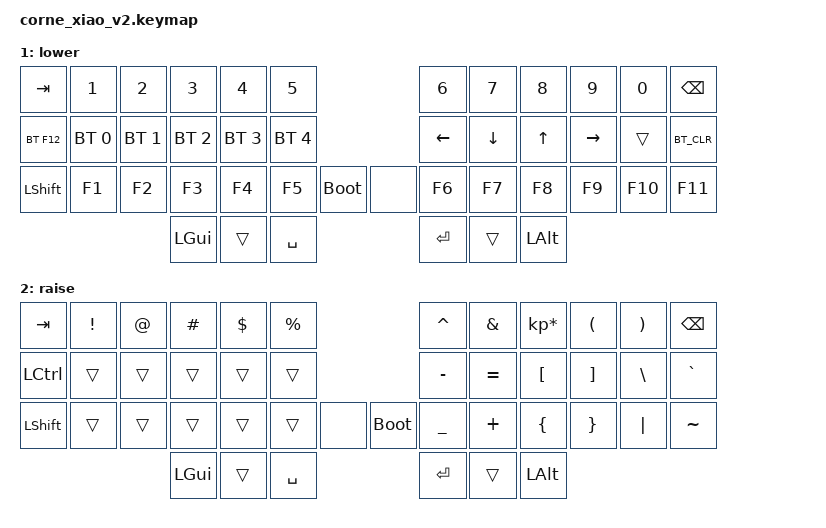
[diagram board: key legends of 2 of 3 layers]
#include <behaviors.dtsi>
#include <dt-bindings/zmk/keys.h>
#include <dt-bindings/zmk/bt.h>

/ {
    behaviors {
        hml: home_row_mod_left {
            compatible = "zmk,behavior-hold-tap";
            #binding-cells = <2>;
            flavor = "balanced";
            require-prior-idle-ms = <150>;
            tapping-term-ms = <280>;
            quick-tap-ms = <175>;
            bindings = <&kp>, <&kp>;
            // Right-hand side key positions (placeholder, adjust for your board!)
            hold-trigger-key-positions = < 14 15 16 17 18 19 20 21 22 23 24 25 >;
            hold-trigger-on-release;
        };

        hmr: home_row_mod_right {
            compatible = "zmk,behavior-hold-tap";
            #binding-cells = <2>;
            flavor = "balanced";
            require-prior-idle-ms = <150>;
            tapping-term-ms = <280>;
            quick-tap-ms = <175>;
            bindings = <&kp>, <&kp>;
            // Left-hand side key positions (placeholder, adjust for your board!)
            hold-trigger-key-positions = < 0 1 2 3 4 5 6 7 8 9 10 11 >;
            hold-trigger-on-release;
        };
    };

    combos {
        compatible = "zmk,combos";
        combo_studio_unlock {
            timeout-ms = <50>;
            key-positions = <0 1>;
            bindings = <&studio_unlock>;
        };
    };
};

 / {
    keymap {
        compatible = "zmk,keymap";

        default_layer {
            display-name = "base";
            sensor-bindings = <&inc_dec_kp C_VOL_UP C_VOL_DN &inc_dec_kp PG_UP PG_DN>;

            // -------------------------------------------------------------------------------------------------
            // |  TAB |  Q  |  W  |  E  |  R  |  T  |                    |  Y  |  U   |  I  |  O  |  P  | BKSP |
            // | CTRL |  A  |  S  |  D  |  F  |  G  |                    |  H  |  J   |  K  |  L  |  ;  |  '   |
            // | SHFT |  Z  |  X  |  C  |  V  |  B  |  MUTE  |  |        |  N  |  M   |  ,  |  .  |  /  | ESC  |
            //                    | GUI | LWR | SPC |                    | ENT | RSE  | ALT |
            bindings = <
&kp TAB   &kp Q &kp W &kp E     &kp R &kp T                       &kp Y   &kp U     &kp I     &kp O   &kp P    &kp BSPC

&hml LCTRL A   &hml LALT S &hml LGUI D &hml LSHFT F &kp G         &kp H   &hmr RSHFT J &hmr RGUI K &hmr RALT L &hmr RCTRL SEMI &kp SQT

&kp LSHFT &kp Z &kp X &kp C     &kp V &kp B     &kp C_MUTE &none  &kp N   &kp M &kp COMMA &kp DOT &kp FSLH &kp ESC

                       &kp LGUI &mo 1 &kp SPACE                   &kp RET &mo 2 &kp LALT
            >;
        };

        lower_layer {
            display-name = "lower";
            sensor-bindings = <&inc_dec_kp C_VOL_UP C_VOL_DN &inc_dec_kp PG_UP PG_DN>;

            // ------------------------------------------------------------------------------------------------
            // |  TAB |  1  |  2  |  3  |  4  |  5  |                    |  6  |  7  |  8  |  9  |  0  | BKSP |
            // | BTCLR| BT1 | BT2 | BT3 | BT4 | BT5 |                    | LFT | DWN |  UP | RGT |     |  F12 |
            // | SHFT | F1  | F2  | F3  | F4  | F5  |  boot  |  |        |  F6 | F7  | F8  | F9  | F10 |  F11 |
            //                    | GUI |     | SPC |                    | ENT |     | ALT |
            bindings = <
&kp TAB    &kp N1       &kp N2       &kp N3       &kp N4       &kp N5                         &kp N6   &kp N7   &kp N8 &kp N9    &kp N0  &kp BSPC
&bt F12    &bt BT_SEL 0 &bt BT_SEL 1 &bt BT_SEL 2 &bt BT_SEL 3 &bt BT_SEL 4                   &kp LEFT &kp DOWN &kp UP &kp RIGHT &trans  &kp BT_CLR
&kp LSHFT  &kp F1       &kp F2       &kp F3       &kp F4       &kp F5       &bootloader &none &kp F6   &kp F7   &kp F8 &kp F9    &kp F10 &kp F11
                                     &kp LGUI     &trans       &kp SPACE                      &kp RET  &trans   &kp LALT
            >;
        };

        raise_layer {
            display-name = "raise";
            sensor-bindings = <&inc_dec_kp C_VOL_UP C_VOL_DN &inc_dec_kp PG_UP PG_DN>;

            // ------------------------------------------------------------------------------------------------
            // |  TAB |  !  |  @  |  #  |  $  |  %  |                    |  ^  |  &  |  *  |  (  |  )  | BKSP |
            // | CTRL |     |     |     |     |     |                    |  -  |  =  |  [  |  ]  |  \  |  `   |
            // | SHFT |     |     |     |     |     |        |  |  boot  |  _  |  +  |  {  |  }  | "|" |  ~   |
            //                    | GUI |     | SPC |                    | ENT |     | ALT |
            bindings = <
&kp TAB   &kp EXCL &kp AT &kp HASH &kp DLLR &kp PRCNT                   &kp CARET &kp AMPS  &kp KP_MULTIPLY &kp LPAR &kp RPAR &kp BSPC
&kp LCTRL &trans   &trans &trans   &trans   &trans                      &kp MINUS &kp EQUAL &kp LBKT        &kp RBKT &kp BSLH &kp GRAVE
&kp LSHFT &trans   &trans &trans   &trans   &trans    &none &bootloader &kp UNDER &kp PLUS  &kp LBRC        &kp RBRC &kp PIPE &kp TILDE
                          &kp LGUI &trans   &kp SPACE                   &kp RET   &trans    &kp LALT
            >;
        };

        extra1 {
            display-name = "extra1";
            status = "reserved";
        };

        extra2 {
            display-name = "extra2";
            status = "reserved";
        };
    };
};
